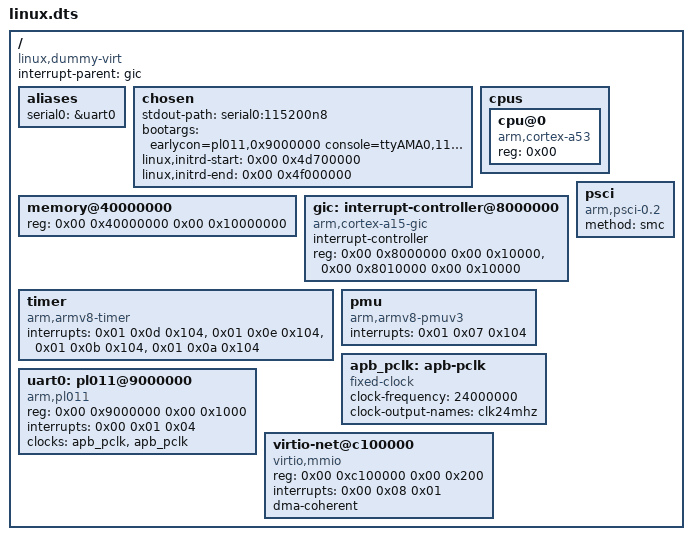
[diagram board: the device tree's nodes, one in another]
/dts-v1/;

/ {
    #address-cells = <0x02>;
    #size-cells = <0x02>;
    compatible = "linux,dummy-virt";
    interrupt-parent = <&gic>;

    aliases {
        serial0 = &uart0;
    };

    chosen {
        stdout-path = "serial0:115200n8";
        bootargs = "earlycon=pl011,0x9000000 console=ttyAMA0,115200";
        linux,initrd-start = <0x00 0x4d700000>;
        linux,initrd-end = <0x00 0x4f000000>;
    };

    memory@40000000 {
        device_type = "memory";
        reg = <0x00 0x40000000 0x00 0x10000000>;
    };

    cpus {
        #address-cells = <0x01>;
        #size-cells = <0x00>;
        cpu@0 {
            device_type = "cpu";
            compatible = "arm,cortex-a53";
            reg = <0x00>;
        };
    };

    gic: interrupt-controller@8000000 {
        compatible = "arm,cortex-a15-gic";
        #interrupt-cells = <0x03>;
        interrupt-controller;
        reg = <0x00 0x8000000 0x00 0x10000>,
              <0x00 0x8010000 0x00 0x10000>;
    };

    timer {
        compatible = "arm,armv8-timer";
        interrupts = <0x01 0x0d 0x104>,
                     <0x01 0x0e 0x104>,
                     <0x01 0x0b 0x104>,
                     <0x01 0x0a 0x104>;
    };

    pmu {
        compatible = "arm,armv8-pmuv3";
        interrupts = <0x01 0x07 0x104>;
    };

    psci {
        compatible = "arm,psci-0.2", "arm,psci";
        method = "smc";
    };

    apb_pclk: apb-pclk {
        compatible = "fixed-clock";
        #clock-cells = <0x00>;
        clock-frequency = <24000000>;
        clock-output-names = "clk24mhz";
    };

    uart0: pl011@9000000 {
        compatible = "arm,pl011", "arm,primecell";
        reg = <0x00 0x9000000 0x00 0x1000>;
        interrupts = <0x00 0x01 0x04>;
        clocks = <&apb_pclk>, <&apb_pclk>;
        clock-names = "uartclk", "apb_pclk";
    };

    virtio-net@c100000 {
        compatible = "virtio,mmio";
        reg = <0x00 0xc100000 0x00 0x200>;
        interrupts = <0x00 0x08 0x01>;
        dma-coherent;
    };
};
